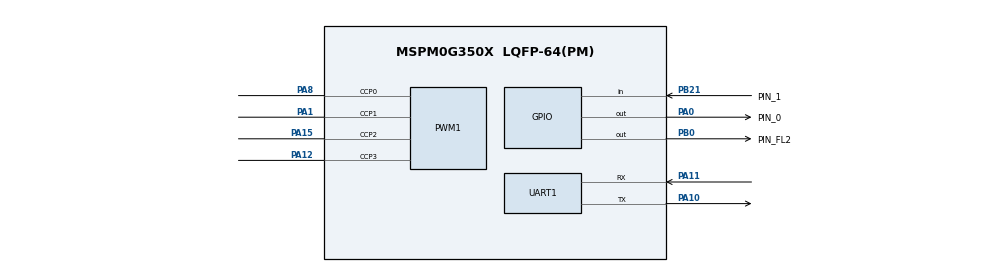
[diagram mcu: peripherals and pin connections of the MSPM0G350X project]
/**
 * @cliArgs --device "MSPM0G350X" --part "Default" --package "LQFP-64(PM)" --product "mspm0_sdk@2.05.00.05"
 * @versions {"tool":"1.24.0+4150"}
 */

/**
 * Import the modules used in this configuration.
 */
const GPIO   = scripting.addModule("/ti/driverlib/GPIO", {}, false);
const GPIO1  = GPIO.addInstance();
const GPIO2  = GPIO.addInstance();
const GPIO3  = GPIO.addInstance();
const PWM    = scripting.addModule("/ti/driverlib/PWM", {}, false);
const PWM1   = PWM.addInstance();
const SYSCTL = scripting.addModule("/ti/driverlib/SYSCTL");
const UART   = scripting.addModule("/ti/driverlib/UART", {}, false);
const UART1  = UART.addInstance();

/**
 * Write custom configuration values to the imported modules.
 */
GPIO1.$name                         = "GPIO_LED";
GPIO1.port                          = "PORTA";
GPIO1.associatedPins[0].$name       = "PIN_0";
GPIO1.associatedPins[0].assignedPin = "0";
GPIO1.associatedPins[0].pin.$assign = "PA0";

const Board = scripting.addModule("/ti/driverlib/Board", {}, false);

GPIO2.$name                              = "GPIO_BUTTON";
GPIO2.port                               = "PORTB";
GPIO2.associatedPins[0].$name            = "PIN_1";
GPIO2.associatedPins[0].direction        = "INPUT";
GPIO2.associatedPins[0].assignedPin      = "21";
GPIO2.associatedPins[0].internalResistor = "PULL_UP";
GPIO2.associatedPins[0].pin.$assign      = "PB21";

GPIO3.$name                         = "GPIO_MOTOR";
GPIO3.associatedPins.create(10);
GPIO3.associatedPins[0].$name       = "PIN_FL1";
GPIO3.associatedPins[1].$name       = "PIN_FL2";
GPIO3.associatedPins[1].pin.$assign = "PB0";
GPIO3.associatedPins[2].$name       = "PIN_FR1";
GPIO3.associatedPins[3].$name       = "PIN_FR2";
GPIO3.associatedPins[4].$name       = "PIN_BL1";
GPIO3.associatedPins[5].$name       = "PIN_BL2";
GPIO3.associatedPins[6].$name       = "PIN_BR1";
GPIO3.associatedPins[7].$name       = "PIN_BR2";
GPIO3.associatedPins[8].$name       = "PIN_FSTBY";
GPIO3.associatedPins[9].$name       = "PIN_BSTBY";

PWM1.$name                              = "PWM_MOTOR";
PWM1.timerCount                         = 320;
PWM1.timerStartTimer                    = true;
PWM1.ccIndex                            = [0,1,2,3];
PWM1.PWM_CHANNEL_0.$name                = "ti_driverlib_pwm_PWMTimerCC0";
PWM1.PWM_CHANNEL_0.ccValue              = 3199;
PWM1.PWM_CHANNEL_1.$name                = "ti_driverlib_pwm_PWMTimerCC1";
PWM1.PWM_CHANNEL_1.ccValue              = 3199;
PWM1.ccp0PinConfig.direction            = scripting.forceWrite("OUTPUT");
PWM1.ccp0PinConfig.hideOutputInversion  = scripting.forceWrite(false);
PWM1.ccp0PinConfig.onlyInternalResistor = scripting.forceWrite(false);
PWM1.ccp0PinConfig.passedPeripheralType = scripting.forceWrite("Digital");
PWM1.ccp0PinConfig.$name                = "ti_driverlib_gpio_GPIOPinGeneric2";
PWM1.ccp1PinConfig.direction            = scripting.forceWrite("OUTPUT");
PWM1.ccp1PinConfig.hideOutputInversion  = scripting.forceWrite(false);
PWM1.ccp1PinConfig.onlyInternalResistor = scripting.forceWrite(false);
PWM1.ccp1PinConfig.passedPeripheralType = scripting.forceWrite("Digital");
PWM1.ccp1PinConfig.$name                = "ti_driverlib_gpio_GPIOPinGeneric3";
PWM1.peripheral.ccp0Pin.$assign         = "PA8";
PWM1.peripheral.ccp1Pin.$assign         = "PA1";
PWM1.peripheral.ccp2Pin.$assign         = "PA15";
PWM1.peripheral.ccp3Pin.$assign         = "PA12";
PWM1.PWM_CHANNEL_2.$name                = "ti_driverlib_pwm_PWMTimerCC2";
PWM1.PWM_CHANNEL_2.ccValue              = 3199;
PWM1.PWM_CHANNEL_3.$name                = "ti_driverlib_pwm_PWMTimerCC3";
PWM1.PWM_CHANNEL_3.ccValue              = 3199;
PWM1.ccp2PinConfig.$name                = "ti_driverlib_gpio_GPIOPinGeneric4";
PWM1.ccp3PinConfig.$name                = "ti_driverlib_gpio_GPIOPinGeneric5";

SYSCTL.forceDefaultClkConfig = true;

UART1.$name                            = "UART_OPENMV";
UART1.enabledInterrupts                = ["RX"];
UART1.peripheral.$assign               = "UART0";
UART1.peripheral.rxPin.$assign         = "PA11";
UART1.peripheral.txPin.$assign         = "PA10";
UART1.txPinConfig.direction            = scripting.forceWrite("OUTPUT");
UART1.txPinConfig.hideOutputInversion  = scripting.forceWrite(false);
UART1.txPinConfig.onlyInternalResistor = scripting.forceWrite(false);
UART1.txPinConfig.passedPeripheralType = scripting.forceWrite("Digital");
UART1.txPinConfig.$name                = "ti_driverlib_gpio_GPIOPinGeneric0";
UART1.rxPinConfig.hideOutputInversion  = scripting.forceWrite(false);
UART1.rxPinConfig.onlyInternalResistor = scripting.forceWrite(false);
UART1.rxPinConfig.passedPeripheralType = scripting.forceWrite("Digital");
UART1.rxPinConfig.$name                = "ti_driverlib_gpio_GPIOPinGeneric1";

/**
 * Pinmux solution for unlocked pins/peripherals. This ensures that minor changes to the automatic solver in a future
 * version of the tool will not impact the pinmux you originally saw.  These lines can be completely deleted in order to
 * re-solve from scratch.
 */
Board.peripheral.$suggestSolution            = "DEBUGSS";
Board.peripheral.swclkPin.$suggestSolution   = "PA20";
Board.peripheral.swdioPin.$suggestSolution   = "PA19";
GPIO3.associatedPins[0].pin.$suggestSolution = "PB13";
GPIO3.associatedPins[2].pin.$suggestSolution = "PB14";
GPIO3.associatedPins[3].pin.$suggestSolution = "PB15";
GPIO3.associatedPins[4].pin.$suggestSolution = "PB16";
GPIO3.associatedPins[5].pin.$suggestSolution = "PA13";
GPIO3.associatedPins[6].pin.$suggestSolution = "PA14";
GPIO3.associatedPins[7].pin.$suggestSolution = "PA16";
GPIO3.associatedPins[8].pin.$suggestSolution = "PA17";
GPIO3.associatedPins[9].pin.$suggestSolution = "PA18";
PWM1.peripheral.$suggestSolution             = "TIMA0";
SYSCTL.peripheral.$suggestSolution           = "SYSCTL";
